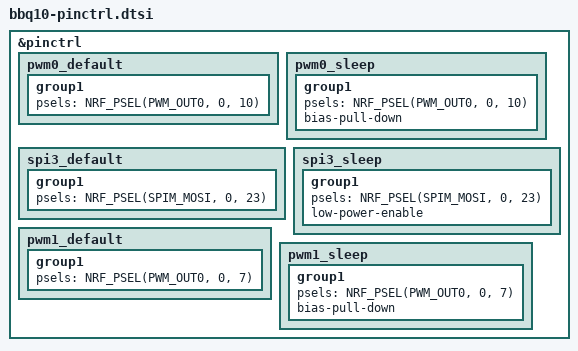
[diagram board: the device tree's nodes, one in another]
/*
 * Copyright (c) 2025 daliben123
 * SPDX-License-Identifier: MIT
 */

&pinctrl {
    pwm0_default:pwm0_default{
        group1{
            psels = <NRF_PSEL(PWM_OUT0, 0, 10)>; // Backlight for backlight.c unreal
        };
    };

    pwm0_sleep: pwm0_sleep {
        group1 {
            psels = <NRF_PSEL(PWM_OUT0, 0, 10)>;
            bias-pull-down;
        };
    };
spi3_default: spi3_default {
        group1 {
            psels = <NRF_PSEL(SPIM_MOSI, 0, 23)>;    // Setting for RGB light, unreal
        };
    };

    spi3_sleep: spi3_sleep {
        group1 {
            psels = <NRF_PSEL(SPIM_MOSI, 0, 23)>;
            low-power-enable;
        };
    };

    pwm1_default:pwm1_default{
        group1{
            psels = <NRF_PSEL(PWM_OUT0, 0, 7)>; // Backlight for Keyboard
        };
    };

    pwm1_sleep: pwm1_sleep {
        group1 {
            psels = <NRF_PSEL(PWM_OUT0, 0, 7)>;
            bias-pull-down;
        };
    };

};
